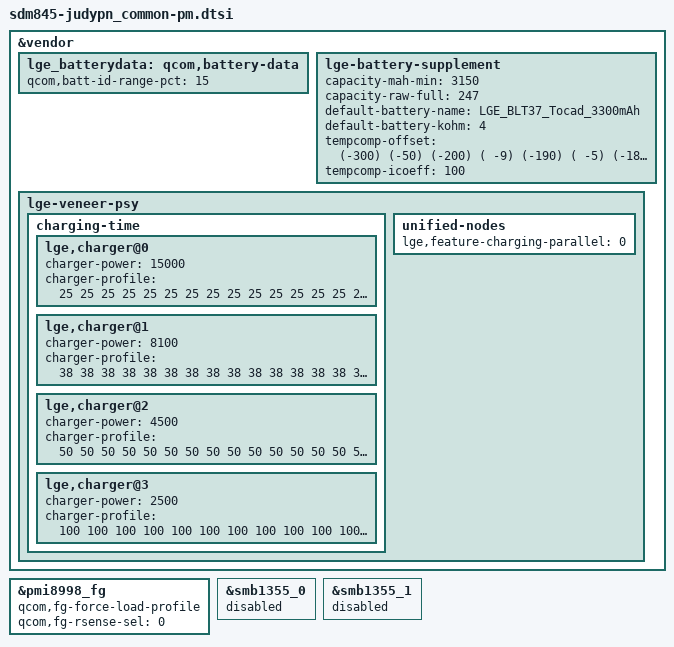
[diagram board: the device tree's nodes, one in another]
/* Copyright (c) 2017, The Linux Foundation. All rights reserved.
 *
 * This program is free software; you can redistribute it and/or modify
 * it under the terms of the GNU General Public License version 2 and
 * only version 2 as published by the Free Software Foundation.
 *
 * This program is distributed in the hope that it will be useful,
 * but WITHOUT ANY WARRANTY; without even the implied warranty of
 * MERCHANTABILITY or FITNESS FOR A PARTICULAR PURPOSE.  See the
 * GNU General Public License for more details.
 */

#include "../sdm845-judy_common/sdm845-judy_common-pm.dtsi"

&vendor {
	lge_batterydata: qcom,battery-data {
		qcom,batt-id-range-pct = <15>;
		#include "../../sdm845-battery/LGE_BLT37_LGC_3300mAh.dtsi"
		#include "../../sdm845-battery/LGE_BLT37_Tocad_3300mAh.dtsi"
	};

	lge-battery-supplement {
		capacity-mah-min = <3150>;
		capacity-raw-full = <247>;

		default-battery-name = "LGE_BLT37_Tocad_3300mAh";
		default-battery-kohm = <4>;

		/* format : (temp index) (temp delta) */
		tempcomp-offset = <
			(-300) (-50)
			(-200) ( -9)
			(-190) ( -5)
			(-180)    0
			(-170)    5
			(-160)   10
			(-150)   12
			(-100)   27
			(-50)    35
			0        37
			50       25
			100      22
			150      14
			200       4
			250    ( -7)
			300    (-19)
			350    (-30)
			400    (-36)
			450    (-44)
			500    (-64)
			550    (-36)
			600    (-31)
			700    (-10)
			800    (-10)
			900    (-10)
		>;
		tempcomp-icoeff = <100>;
	};

	lge-veneer-psy {
		charging-time {
			#address-cells = <1>;
			#size-cells = <0>;

			lge,charger@0 {		//  fast charger: 9000mV * 1660mA or 5000mV * 3000mA
				charger-power = <15000>;
				charger-profile = <
					 25  25  25  25  25  25  25  25  25  25  25  25  25  25  25  25
					 25  25  25  25  25  25  25  25  25  25  25  25  25  25  25  25
					 25  25  25  25  25  25  25  25  25  25  25  25  25  25  25  25
					 25  25  25  25  25  25  25  25  25  25  25  25  25  25  25  25
					 25  25  25  25  25  25  25  25  25  25  25  25  25  25  25  25
					 25  25  25  25  25  25  25  25  25  25  25  25  25  25  25  25
					 25  25  25  25  25  25  25  25  25  25  25  25  25  25  25  25
					 25  25  25  25  25  25  25  25  25  25  25  25  25  25  25  25
					 25  25  25  25  25  25  25  25  25  25  25  25  25  25  25  25
					 25  25  25  25  25  25  25  25  25  25  25  25  25  25  25  25
					 25  25  25  25  25  25  25  25  25  25  25  25  25  25  25  25
					 25  25  25  25  25  25  25  25  25  25  25  25  25  25  25  25
					 25  25  25  25  25  25  25  25  25  25  25  25  25  25  25  25
					 25  25  25  25  25  25  25  25  25  25  25  25  25  25  25  25
					 25  25  25  25  25  25  25  25  25  25  25  25  25  25  25  25
					 25  25  25  25  25  25  25  25  25  25  25  25  25  25  25  25
				>;
			};
			lge,charger@1 {		// EPP wireless charger: 9000mV * 900mA = 8.1W
				charger-power = <8100>;
				charger-profile = <
					 38  38  38  38  38  38  38  38  38  38  38  38  38  38  38  38
					 38  38  38  38  38  38  38  38  38  38  38  38  38  38  38  38
					 38  38  38  38  38  38  38  38  38  38  38  38  38  38  38  38
					 38  38  38  38  38  38  38  38  38  38  38  38  38  38  38  38
					 38  38  38  38  38  38  38  38  38  38  38  38  38  38  38  38
					 38  38  38  38  38  38  38  38  38  38  38  38  38  38  38  38
					 38  38  38  38  38  38  38  38  38  38  38  38  38  38  38  38
					 38  38  38  38  38  38  38  38  38  38  38  38  38  38  38  38
					 38  38  38  38  38  38  38  38  38  38  38  38  38  38  38  38
					 38  38  38  38  38  38  38  38  38  38  38  38  38  38  38  38
					 38  38  38  38  38  38  38  38  38  38  38  38  38  38  38  38
					 38  38  38  38  38  38  38  38  38  38  38  38  38  38  38  38
					 38  38  38  38  38  38  38  38  38  38  38  38  38  38  38  38
					 38  38  38  38  38  38  38  38  38  38  38  38  38  38  38  38
					 38  38  38  38  38  38  38  38  38  38  38  38  38  38  38  38
					 38  38  38  38  38  38  38  38  38  38  38  38  38  38  38  38
				>;
			};
			lge,charger@2 {		// BPP wireless charger: 5000mV * 900mA = 4.5W
				charger-power = <4500>;
				charger-profile = <
					 50  50  50  50  50  50  50  50  50  50  50  50  50  50  50  50
					 50  50  50  50  50  50  50  50  50  50  50  50  50  50  50  50
					 50  50  50  50  50  50  50  50  50  50  50  50  50  50  50  50
					 50  50  50  50  50  50  50  50  50  50  50  50  50  50  50  50
					 50  50  50  50  50  50  50  50  50  50  50  50  50  50  50  50
					 50  50  50  50  50  50  50  50  50  50  50  50  50  50  50  50
					 50  50  50  50  50  50  50  50  50  50  50  50  50  50  50  50
					 50  50  50  50  50  50  50  50  50  50  50  50  50  50  50  50
					 50  50  50  50  50  50  50  50  50  50  50  50  50  50  50  50
					 50  50  50  50  50  50  50  50  50  50  50  50  50  50  50  50
					 50  50  50  50  50  50  50  50  50  50  50  50  50  50  50  50
					 50  50  50  50  50  50  50  50  50  50  50  50  50  50  50  50
					 50  50  50  50  50  50  50  50  50  50  50  50  50  50  50  50
					 50  50  50  50  50  50  50  50  50  50  50  50  50  50  50  50
					 50  50  50  50  50  50  50  50  50  50  50  50  50  50  50  50
					 50  50  50  50  50  50  50  50  50  50  50  50  50  50  50  50
				>;
			};
			lge,charger@3 {		// SDP: 5000mV * 500mA = 2.5W
				charger-power = <2500>;
				charger-profile = <
					100 100 100 100 100 100 100 100 100 100 100 100 100 100 100 100
					100 100 100 100 100 100 100 100 100 100 100 100 100 100 100 100
					100 100 100 100 100 100 100 100 100 100 100 100 100 100 100 100
					100 100 100 100 100 100 100 100 100 100 100 100 100 100 100 100
					100 100 100 100 100 100 100 100 100 100 100 100 100 100 100 100
					100 100 100 100 100 100 100 100 100 100 100 100 100 100 100 100
					100 100 100 100 100 100 100 100 100 100 100 100 100 100 100 100
					100 100 100 100 100 100 100 100 100 100 100 100 100 100 100 100
					100 100 100 100 100 100 100 100 100 100 100 100 100 100 100 100
					100 100 100 100 100 100 100 100 100 100 100 100 100 100 100 100
					100 100 100 100 100 100 100 100 100 100 100 100 100 100 100 100
					100 100 100 100 100 100 100 100 100 100 100 100 100 100 100 100
					100 100 100 100 100 100 100 100 100 100 100 100 100 100 100 100
					100 100 100 100 100 100 100 100 100 100 100 100 100 100 100 100
					100 100 100 100 100 100 100 100 100 100 100 100 100 100 100 100
					100 100 100 100 100 100 100 100 100 100 100 100 100 100 100 100
				>;
			};
		};

		unified-nodes {
			lge,feature-charging-parallel = <0>;
		};
	};
};

&pmi8998_fg {
	qcom,fg-force-load-profile;
	qcom,fg-rsense-sel = <0>;
};

&smb1355_0 {
	status = "disabled";
};

&smb1355_1 {
	status = "disabled";
};
